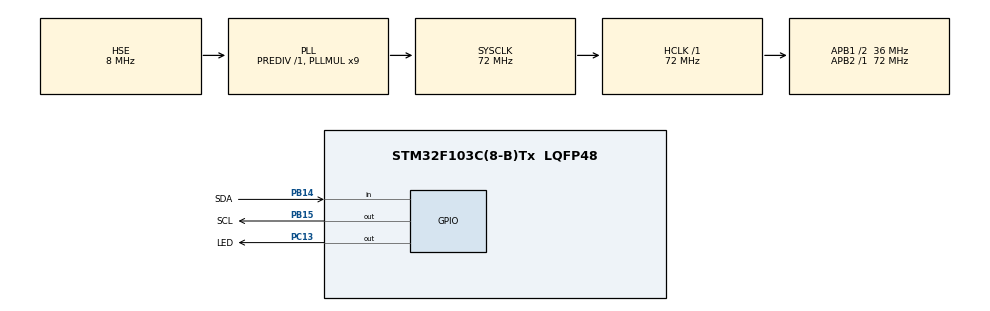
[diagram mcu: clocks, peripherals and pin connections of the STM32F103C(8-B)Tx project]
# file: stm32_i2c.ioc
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Mcu.Family=STM32F1
Mcu.Name=STM32F103C(8-B)Tx
Mcu.Package=LQFP48
NVIC.PriorityGroup=NVIC_PRIORITYGROUP_4
PA13.Mode=Serial_Wire
PA13.Signal=SYS_JTMS-SWDIO
PA14.Mode=Serial_Wire
PA14.Signal=SYS_JTCK-SWCLK
PB14.GPIO_Label=SDA
PB14.Signal=GPIO_Input
PB15.GPIO_Label=SCL
PB15.GPIO_ModeDefaultOutputPP=GPIO_MODE_OUTPUT_PP
PB15.GPIO_PuPd=GPIO_NOPULL
PB15.GPIO_Speed=GPIO_SPEED_FREQ_HIGH
PB15.Signal=GPIO_Output
PC13-TAMPER-RTC.GPIO_Label=LED
PC13-TAMPER-RTC.GPIO_ModeDefaultOutputPP=GPIO_MODE_OUTPUT_PP
PC13-TAMPER-RTC.GPIO_PuPd=GPIO_PULLUP
PC13-TAMPER-RTC.GPIO_Speed=GPIO_SPEED_FREQ_HIGH
PC13-TAMPER-RTC.PinState=GPIO_PIN_SET
PC13-TAMPER-RTC.Signal=GPIO_Output
PC14-OSC32_IN.Mode=LSE-External-Oscillator
PC14-OSC32_IN.Signal=RCC_OSC32_IN
PC15-OSC32_OUT.Mode=LSE-External-Oscillator
PC15-OSC32_OUT.Signal=RCC_OSC32_OUT
PD0-OSC_IN.Mode=HSE-External-Oscillator
PD0-OSC_IN.Signal=RCC_OSC_IN
PD1-OSC_OUT.Mode=HSE-External-Oscillator
PD1-OSC_OUT.Signal=RCC_OSC_OUT
ProjectManager.HeapSize=0x200
ProjectManager.StackSize=0x400
ProjectManager.TargetToolchain=Makefile
RCC.AHBFreq_Value=72000000
RCC.APB1CLKDivider=RCC_HCLK_DIV2
RCC.APB1Freq_Value=36000000
RCC.APB1TimFreq_Value=72000000
RCC.APB2Freq_Value=72000000
RCC.APB2TimFreq_Value=72000000
RCC.HCLKFreq_Value=72000000
RCC.PLLMUL=RCC_PLL_MUL9
RCC.PLLSourceVirtual=RCC_PLLSOURCE_HSE
RCC.SYSCLKFreq_VALUE=72000000
RCC.SYSCLKSource=RCC_SYSCLKSOURCE_PLLCLK
RCC.USBFreq_Value=72000000
TIM1.AutoReloadPreload=TIM_AUTORELOAD_PRELOAD_DISABLE
TIM1.CounterMode=TIM_COUNTERMODE_UP
TIM1.Period=1
TIM1.Prescaler=71
VP_TIM1_VS_ClockSourceINT.Mode=Internal
board=custom

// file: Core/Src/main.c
/* USER CODE BEGIN Header */
/**
  ******************************************************************************
  * @file           : main.c
  * @brief          : Main program body
  ******************************************************************************
  * @attention
  *
  * <h2><center>&copy; Copyright (c) 2021 STMicroelectronics.
  * All rights reserved.</center></h2>
  *
  * This software component is licensed by ST under BSD 3-Clause license,
  * the "License"; You may not use this file except in compliance with the
  * License. You may obtain a copy of the License at:
  *                        opensource.org/licenses/BSD-3-Clause
  *
  ******************************************************************************
  */
/* USER CODE END Header */
#include "main.h"
#include "tim.h"
#include "gpio.h"

void SystemClock_Config(void);
extern void _oled_write_cmd(unsigned char data);

/* USER CODE BEGIN 0 */
void delay_us(int us)
{
  int count = 0xffff - us - 5;
  HAL_TIM_Base_Start(&htim1);
  __HAL_TIM_SetCounter(&htim1, count);
  while (count < 0xffff - 5)
  {
    /* code */
    count = __HAL_TIM_GetCounter(&htim1);
  }
  HAL_TIM_Base_Stop(&htim1);
}
/* USER CODE END 0 */

int main(void)
{

  /* MCU Configuration--------------------------------------------------------*/

  /* Reset of all peripherals, Initializes the Flash interface and the Systick. */
  HAL_Init();

  /* Configure the system clock */
  SystemClock_Config();

  /* Initialize all configured peripherals */
  MX_GPIO_Init();
  MX_TIM1_Init();
  /* USER CODE BEGIN 2 */
  oledInit();
  // oled_write_cmd(0xDA); //pin configuartion
  // oled_write_cmd(0x00);
  // oled_write_cmd(0xA8); //ratio 1-64
  // oled_write_cmd(0x1F);
  oledOn();
  oledCls();
  oledDisplayMode(0);
  _oled_write_cmd(0xA6);
  HAL_Delay(500);
  //OLED_ShowString(0, 0, (unsigned char *)"hhhh", 8);
  float x, y, z;
  char str[10];
  //memset(str, 0, sizeof(str));
  // 把浮点数ff转换为字符串，存放在strff中。
  GY_Init();

  /* USER CODE END 2 */

  /* Infinite loop */
  while (1)
  {
    x = GY_Read_Data(Data_Read.ACCEL_XOUT_H) / 16384.0;
    y=GY_Read_Data(Data_Read.ACCEL_YOUT_H) / 16384.0;
    z=GY_Read_Data(Data_Read.ACCEL_ZOUT_H) / 16384.0;
    floatToString(x,str,10);
    oledShowString(0, 0, str, 8);
    floatToString(y,str,10);
    oledShowString(0, 1, str, 8);
    floatToString(z,str,10);
    oledShowString(0, 2, str, 8);
    HAL_Delay(500);
  }
}

void SystemClock_Config(void)
{
  RCC_OscInitTypeDef RCC_OscInitStruct = {0};
  RCC_ClkInitTypeDef RCC_ClkInitStruct = {0};

  /** Initializes the RCC Oscillators according to the specified parameters
  * in the RCC_OscInitTypeDef structure.
  */
  RCC_OscInitStruct.OscillatorType = RCC_OSCILLATORTYPE_HSE;
  RCC_OscInitStruct.HSEState = RCC_HSE_ON;
  RCC_OscInitStruct.HSEPredivValue = RCC_HSE_PREDIV_DIV1;
  RCC_OscInitStruct.HSIState = RCC_HSI_ON;
  RCC_OscInitStruct.PLL.PLLState = RCC_PLL_ON;
  RCC_OscInitStruct.PLL.PLLSource = RCC_PLLSOURCE_HSE;
  RCC_OscInitStruct.PLL.PLLMUL = RCC_PLL_MUL9;
  if (HAL_RCC_OscConfig(&RCC_OscInitStruct) != HAL_OK)
  {
    Error_Handler();
  }
  /** Initializes the CPU, AHB and APB buses clocks
  */
  RCC_ClkInitStruct.ClockType = RCC_CLOCKTYPE_HCLK | RCC_CLOCKTYPE_SYSCLK | RCC_CLOCKTYPE_PCLK1 | RCC_CLOCKTYPE_PCLK2;
  RCC_ClkInitStruct.SYSCLKSource = RCC_SYSCLKSOURCE_PLLCLK;
  RCC_ClkInitStruct.AHBCLKDivider = RCC_SYSCLK_DIV1;
  RCC_ClkInitStruct.APB1CLKDivider = RCC_HCLK_DIV2;
  RCC_ClkInitStruct.APB2CLKDivider = RCC_HCLK_DIV1;

  if (HAL_RCC_ClockConfig(&RCC_ClkInitStruct, FLASH_LATENCY_2) != HAL_OK)
  {
    Error_Handler();
  }
}

void Error_Handler(void)
{
  __disable_irq();
  while (1)
  {
  }
}

/************************ (C) COPYRIGHT STMicroelectronics *****END OF FILE****/
